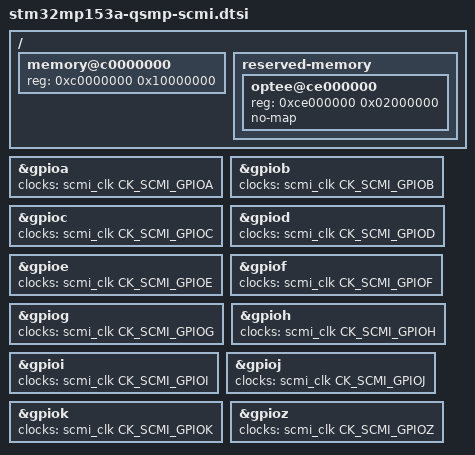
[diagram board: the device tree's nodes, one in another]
// SPDX-License-Identifier: (GPL-2.0-or-later OR BSD-3-Clause)
/*
 * Copyright (C) 2024 Lothar Waßmann <LW@KARO-electronics.de>
 */

#include "stm32mp15-qsmp-scmi.dtsi"

/ {
    memory@c0000000 {
		device_type = "memory";
		reg = <0xc0000000 0x10000000>;
	};
    
	reserved-memory {
		optee@ce000000 {
			reg = <0xce000000 0x02000000>;
			no-map;
		};
	};
};

&gpioa {
	clocks = <&scmi_clk CK_SCMI_GPIOA>;
};

&gpiob {
	clocks = <&scmi_clk CK_SCMI_GPIOB>;
};

&gpioc {
	clocks = <&scmi_clk CK_SCMI_GPIOC>;
};

&gpiod {
	clocks = <&scmi_clk CK_SCMI_GPIOD>;
};

&gpioe {
	clocks = <&scmi_clk CK_SCMI_GPIOE>;
};

&gpiof {
	clocks = <&scmi_clk CK_SCMI_GPIOF>;
};

&gpiog {
	clocks = <&scmi_clk CK_SCMI_GPIOG>;
};

&gpioh {
	clocks = <&scmi_clk CK_SCMI_GPIOH>;
};

&gpioi {
	clocks = <&scmi_clk CK_SCMI_GPIOI>;
};

&gpioj {
	clocks = <&scmi_clk CK_SCMI_GPIOJ>;
};

&gpiok {
	clocks = <&scmi_clk CK_SCMI_GPIOK>;
};

&gpioz {
	clocks = <&scmi_clk CK_SCMI_GPIOZ>;
};
